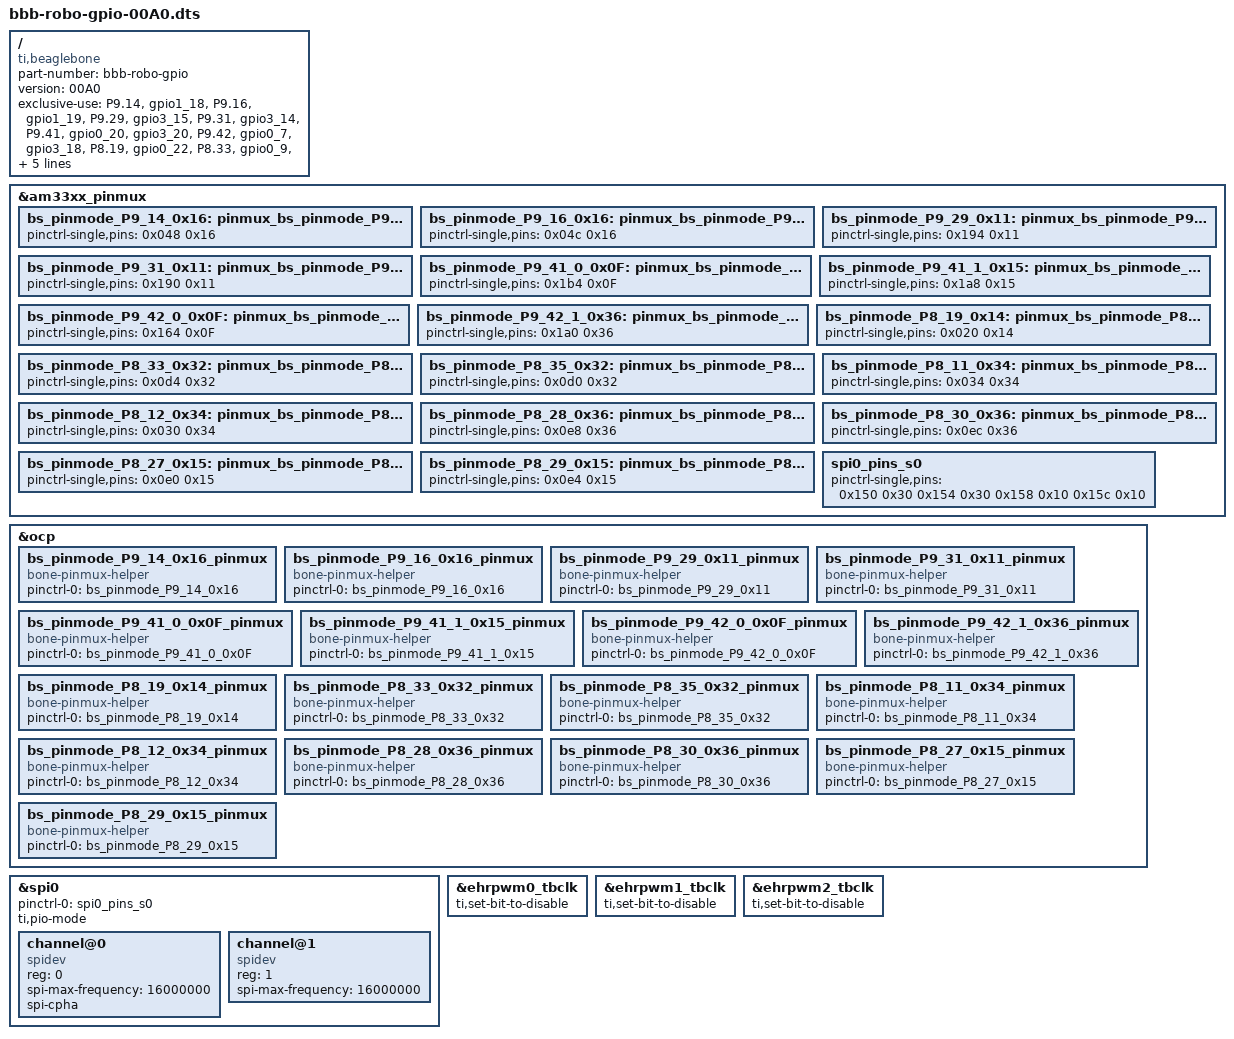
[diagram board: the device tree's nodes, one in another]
/*
 * This is a template-generated file from BoneScript
 */

/dts-v1/;
/plugin/;

/{
    compatible = "ti,beaglebone", "ti,beaglebone-black";
    part-number = "bbb-robo-gpio";
    version = "00A0";

    // P9.14, ehrpwm1a - AIN1 - Out
    // P9.16, ehrpwm1b - AIN2 - Out
    // P9.29, ehrpwm0b - BIN2 - Out
    // P9.31, ehrpwm0a - BIN1 - Out
    // P9.41, pr1_pru0_pru_r3x_6 - nSleep - Out
    // P9.42, pr1_pru0_pru_r3x_4 - nFault - In
    
    // P8.19, ehrpwm2a - SPK - Out
    
    // P8.33, eQEP1B - L-ENC_B - In
    // P8.35, eQEP1A - L-ENC_A - In
    // P8.11, eQEP2B - R-ENC_B - In
    // P8.12, eQEP2A - R-ENC_A - In
    
    // P9.17, SPI0_CS0 - In
    // P9.18, SPI0_DI - In
    // P9.21, SPI0_DO - Out
    // P9.22, SPI0_CLK - In
    // P8.28, pr1_pru1_pru_r3x_10 - INT1 - In
    // P8.30, pr1_pru1_pru_r3x_11 - INT2 - In
    
    // P8.27, pr1_pru1_pru_r3x_8 - LED 2 - Out
    // P8.29, pr1_pru1_pru_r3x_9 - LED 3 - Out
    
    exclusive-use =
        "P9.14",
        "gpio1_18",
        "P9.16",
        "gpio1_19",
        "P9.29",
        "gpio3_15",
        "P9.31",
        "gpio3_14",
        "P9.41",
        "gpio0_20",
        "gpio3_20",
        "P9.42",
        "gpio0_7",
        "gpio3_18",
        "P8.19",
        "gpio0_22",
        "P8.33",
        "gpio0_9",
        "P8.35",
        "gpio0_8",
        "P8.11",
        "gpio1_13",
        "P8.12",
        "gpio1_12",
        "P9.17",
        "gpio0_5",
        "P9.18",
        "gpio0_4",
        "P9.21",
        "gpio0_3",
        "P9.22",
        "gpio0_2",
        "P8.28",
        "gpio2_24",
        "P8.30",
        "gpio2_25",
        "P8.27",
        "gpio2_22",
        "P8.29",
        "gpio2_23";
        
    fragment@0 {
        target = <&am33xx_pinmux>;
        __overlay__ {
            bs_pinmode_P9_14_0x16: pinmux_bs_pinmode_P9_14_0x16 {
                pinctrl-single,pins = <0x048 0x16>;
            };
            bs_pinmode_P9_16_0x16: pinmux_bs_pinmode_P9_16_0x16 {
                pinctrl-single,pins = <0x04c 0x16>;
            };
            bs_pinmode_P9_29_0x11: pinmux_bs_pinmode_P9_29_0x11 {
                pinctrl-single,pins = <0x194 0x11>;
            };
            bs_pinmode_P9_31_0x11: pinmux_bs_pinmode_P9_31_0x11 {
                pinctrl-single,pins = <0x190 0x11>;
            };
            bs_pinmode_P9_41_0_0x0F: pinmux_bs_pinmode_P9_41_0_0x0F {
                pinctrl-single,pins = <0x1b4 0x0F>;
            };
            bs_pinmode_P9_41_1_0x15: pinmux_bs_pinmode_P9_41_1_0x15 {
                pinctrl-single,pins = <0x1a8 0x15>;
            };
            bs_pinmode_P9_42_0_0x0F: pinmux_bs_pinmode_P9_42_0_0x0F {
                pinctrl-single,pins = <0x164 0x0F>;
            };
            bs_pinmode_P9_42_1_0x36: pinmux_bs_pinmode_P9_42_1_0x36 {
                pinctrl-single,pins = <0x1a0 0x36>;
            };
            bs_pinmode_P8_19_0x14: pinmux_bs_pinmode_P8_19_0x14 {
                pinctrl-single,pins = <0x020 0x14>;
            };
            bs_pinmode_P8_33_0x32: pinmux_bs_pinmode_P8_33_0x32 {
                pinctrl-single,pins = <0x0d4 0x32>;
            };
            bs_pinmode_P8_35_0x32: pinmux_bs_pinmode_P8_35_0x32 {
                pinctrl-single,pins = <0x0d0 0x32>;
            };
            bs_pinmode_P8_11_0x34: pinmux_bs_pinmode_P8_11_0x34 {
                pinctrl-single,pins = <0x034 0x34>;
            };
            bs_pinmode_P8_12_0x34: pinmux_bs_pinmode_P8_12_0x34 {
                pinctrl-single,pins = <0x030 0x34>;
            };
/*            bs_pinmode_P9_17_0x30: pinmux_bs_pinmode_P9_17_0x30 {
                pinctrl-single,pins = <0x15c 0x30>;
            };
            bs_pinmode_P9_18_0x30: pinmux_bs_pinmode_P9_18_0x30 {
                pinctrl-single,pins = <0x158 0x30>;
            };
            bs_pinmode_P9_21_0x10: pinmux_bs_pinmode_P9_21_0x10 {
                pinctrl-single,pins = <0x154 0x10>;
            };
            bs_pinmode_P9_22_0x30: pinmux_bs_pinmode_P9_22_0x30 {
                pinctrl-single,pins = <0x150 0x30>;
            }; */
            bs_pinmode_P8_28_0x36: pinmux_bs_pinmode_P8_28_0x36 {
                pinctrl-single,pins = <0x0e8 0x36>;
            };
            bs_pinmode_P8_30_0x36: pinmux_bs_pinmode_P8_30_0x36 {
                pinctrl-single,pins = <0x0ec 0x36>;
            };
            bs_pinmode_P8_27_0x15: pinmux_bs_pinmode_P8_27_0x15 {
                pinctrl-single,pins = <0x0e0 0x15>;
            };
            bs_pinmode_P8_29_0x15: pinmux_bs_pinmode_P8_29_0x15 {
                pinctrl-single,pins = <0x0e4 0x15>;
            };
            spi0_pins_s0: spi0_pins_s0 {
                pinctrl-single,pins = <
                  0x150 0x30  /* spi0_sclk, INPUT_PULLUP | MODE0 */
                  0x154 0x30  /* spi0_d0, INPUT_PULLUP | MODE0 */
                  0x158 0x10  /* spi0_d1, OUTPUT_PULLUP | MODE0 */
                  0x15c 0x10  /* spi0_cs0, OUTPUT_PULLUP | MODE0 */
                >;
            };
        };
    };

    fragment@1 {
        target = <&ocp>;
        __overlay__ {
            bs_pinmode_P9_14_0x16_pinmux {
                compatible = "bone-pinmux-helper";
                status = "okay";
                pinctrl-names = "default";
                pinctrl-0 = <&bs_pinmode_P9_14_0x16>;
            };
            bs_pinmode_P9_16_0x16_pinmux {
                compatible = "bone-pinmux-helper";
                status = "okay";
                pinctrl-names = "default";
                pinctrl-0 = <&bs_pinmode_P9_16_0x16>;
            };
            bs_pinmode_P9_29_0x11_pinmux {
                compatible = "bone-pinmux-helper";
                status = "okay";
                pinctrl-names = "default";
                pinctrl-0 = <&bs_pinmode_P9_29_0x11>;
            };
            bs_pinmode_P9_31_0x11_pinmux {
                compatible = "bone-pinmux-helper";
                status = "okay";
                pinctrl-names = "default";
                pinctrl-0 = <&bs_pinmode_P9_31_0x11>;
            };
            bs_pinmode_P9_41_0_0x0F_pinmux {
                compatible = "bone-pinmux-helper";
                status = "okay";
                pinctrl-names = "default";
                pinctrl-0 = <&bs_pinmode_P9_41_0_0x0F>;
            };
            bs_pinmode_P9_41_1_0x15_pinmux {
                compatible = "bone-pinmux-helper";
                status = "okay";
                pinctrl-names = "default";
                pinctrl-0 = <&bs_pinmode_P9_41_1_0x15>;
            };
            bs_pinmode_P9_42_0_0x0F_pinmux {
                compatible = "bone-pinmux-helper";
                status = "okay";
                pinctrl-names = "default";
                pinctrl-0 = <&bs_pinmode_P9_42_0_0x0F>;
            };
            bs_pinmode_P9_42_1_0x36_pinmux {
                compatible = "bone-pinmux-helper";
                status = "okay";
                pinctrl-names = "default";
                pinctrl-0 = <&bs_pinmode_P9_42_1_0x36>;
            };
            bs_pinmode_P8_19_0x14_pinmux {
                compatible = "bone-pinmux-helper";
                status = "okay";
                pinctrl-names = "default";
                pinctrl-0 = <&bs_pinmode_P8_19_0x14>;
            };
            bs_pinmode_P8_33_0x32_pinmux {
                compatible = "bone-pinmux-helper";
                status = "okay";
                pinctrl-names = "default";
                pinctrl-0 = <&bs_pinmode_P8_33_0x32>;
            };
            bs_pinmode_P8_35_0x32_pinmux {
                compatible = "bone-pinmux-helper";
                status = "okay";
                pinctrl-names = "default";
                pinctrl-0 = <&bs_pinmode_P8_35_0x32>;
            };
            bs_pinmode_P8_11_0x34_pinmux {
                compatible = "bone-pinmux-helper";
                status = "okay";
                pinctrl-names = "default";
                pinctrl-0 = <&bs_pinmode_P8_11_0x34>;
            };
            bs_pinmode_P8_12_0x34_pinmux {
                compatible = "bone-pinmux-helper";
                status = "okay";
                pinctrl-names = "default";
                pinctrl-0 = <&bs_pinmode_P8_12_0x34>;
            };
/*            bs_pinmode_P9_17_0x30_pinmux {
                compatible = "bone-pinmux-helper";
                status = "okay";
                pinctrl-names = "default";
                pinctrl-0 = <&bs_pinmode_P9_17_0x30>;
            };
            bs_pinmode_P9_18_0x30_pinmux {
                compatible = "bone-pinmux-helper";
                status = "okay";
                pinctrl-names = "default";
                pinctrl-0 = <&bs_pinmode_P9_18_0x30>;
            };
            bs_pinmode_P9_21_0x10_pinmux {
                compatible = "bone-pinmux-helper";
                status = "okay";
                pinctrl-names = "default";
                pinctrl-0 = <&bs_pinmode_P9_21_0x10>;
            };
            bs_pinmode_P9_22_0x30_pinmux {
                compatible = "bone-pinmux-helper";
                status = "okay";
                pinctrl-names = "default";
                pinctrl-0 = <&bs_pinmode_P9_22_0x30>;
            }; */
            bs_pinmode_P8_28_0x36_pinmux {
                compatible = "bone-pinmux-helper";
                status = "okay";
                pinctrl-names = "default";
                pinctrl-0 = <&bs_pinmode_P8_28_0x36>;
            };
            bs_pinmode_P8_30_0x36_pinmux {
                compatible = "bone-pinmux-helper";
                status = "okay";
                pinctrl-names = "default";
                pinctrl-0 = <&bs_pinmode_P8_30_0x36>;
            };
            bs_pinmode_P8_27_0x15_pinmux {
                compatible = "bone-pinmux-helper";
                status = "okay";
                pinctrl-names = "default";
                pinctrl-0 = <&bs_pinmode_P8_27_0x15>;
            };
            bs_pinmode_P8_29_0x15_pinmux {
                compatible = "bone-pinmux-helper";
                status = "okay";
                pinctrl-names = "default";
                pinctrl-0 = <&bs_pinmode_P8_29_0x15>;
            };
        };
    };

    fragment@2 {
	target = <&spi0>;
	__overlay__ {
		#address-cells = <1>;
		#size-cells = <0>;

		status = "okay";
		pinctrl-names = "default";
		pinctrl-0 = <&spi0_pins_s0>;
		ti,pio-mode; /* disable dma when used as an overlay, dma gets stuck at 160 bits... */

		channel@0 {
			#address-cells = <1>;
			#size-cells = <0>;

			compatible = "spidev";

			reg = <0>;
			spi-max-frequency = <16000000>;
			spi-cpha;
		};

		channel@1 {
			#address-cells = <1>;
			#size-cells = <0>;

			compatible = "spidev";

			reg = <1>;
			spi-max-frequency = <16000000>;
		};
 	  };
    };

    // Kernel as default disables PWM clocks by clearing clock bits. This hack causes kernel to start PWM clocks instead
    // as it has been specified that set of bit causes disable of clocks (causes not start of clocks)
    fragment@3 {
        target = <&ehrpwm0_tbclk>;
        __overlay__ {
		ti,set-bit-to-disable;
    	};
    };

    fragment@4 {
        target = <&ehrpwm1_tbclk>;
        __overlay__ {
		ti,set-bit-to-disable;
    	};
    };

    fragment@5 {
        target = <&ehrpwm2_tbclk>;
        __overlay__ {
		ti,set-bit-to-disable;
    	};
    };
};
